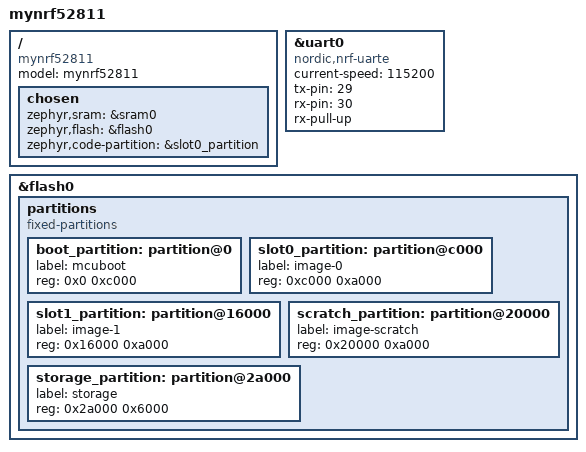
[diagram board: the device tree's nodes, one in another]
// Copyright (c) 2022 Nordic Semiconductor ASA
// SPDX-License-Identifier: Apache-2.0

/dts-v1/;
#include <nordic/nrf52811_qfaa.dtsi>

/ {
	model = "mynrf52811";
	compatible = "mynrf52811";

	chosen {
		zephyr,sram = &sram0;
		zephyr,flash = &flash0;
		zephyr,code-partition = &slot0_partition;
	};
};

&uart0 {
	compatible = "nordic,nrf-uarte";
	status = "okay";
	current-speed = <115200>;
	tx-pin = <29>;
	rx-pin = <30>;
	rx-pull-up;
   //  rts-pin = <2>;
   //  cts-pin = <31>;
   //  cts-pull-up;
};


&flash0 {
	partitions {
		compatible = "fixed-partitions";
		#address-cells = <1>;
		#size-cells = <1>;

		boot_partition: partition@0 {
			label = "mcuboot";
			reg = <0x0 0xc000>;
		};
		slot0_partition: partition@c000 {
			label = "image-0";
			reg = <0xc000 0xa000>;
		};
		slot1_partition: partition@16000 {
			label = "image-1";
			reg = <0x16000 0xa000>;
		};
		scratch_partition: partition@20000 {
			label = "image-scratch";
			reg = <0x20000 0xa000>;
		};
		storage_partition: partition@2a000 {
			label = "storage";
			reg = <0x2a000 0x6000>;
		};
	};
};

